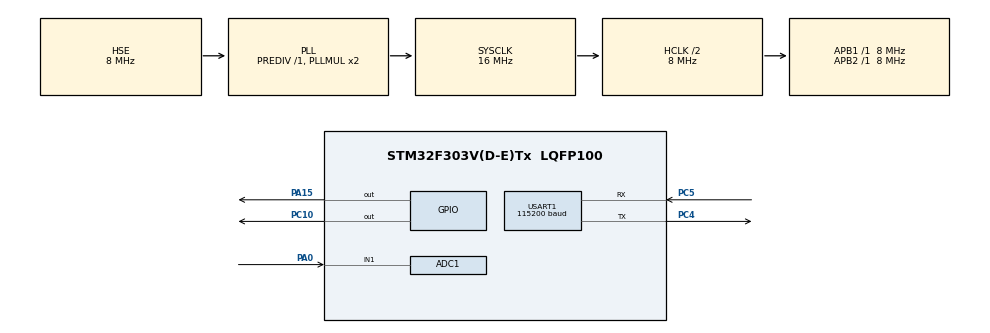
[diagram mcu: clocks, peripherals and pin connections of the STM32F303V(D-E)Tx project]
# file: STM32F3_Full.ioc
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ADC1.Channel-0\#ChannelRegularConversion=ADC_CHANNEL_1
ADC1.NbrOfConversionFlag=1
ADC1.Offset-0\#ChannelRegularConversion=0
ADC1.OffsetNumber-0\#ChannelRegularConversion=ADC_OFFSET_NONE
ADC1.Rank-0\#ChannelRegularConversion=1
ADC1.SamplingTime-0\#ChannelRegularConversion=ADC_SAMPLETIME_1CYCLE_5
ADC1.master=1
FREERTOS.Tasks01=defaultTask,0,128,StartDefaultTask,Default,NULL,Dynamic,NULL,NULL;myTask02,-3,128,StartTask02,Default,NULL,Dynamic,NULL,NULL;myTask03,-3,128,StartTask03,Default,NULL,Dynamic,NULL,NULL
Mcu.Family=STM32F3
Mcu.Name=STM32F303V(D-E)Tx
Mcu.Package=LQFP100
NVIC.ADC1_2_IRQn=true\:5\:0\:false\:false\:true\:true\:true
NVIC.PriorityGroup=NVIC_PRIORITYGROUP_4
NVIC.TIM1_UP_TIM16_IRQn=true\:0\:0\:false\:false\:true\:false\:false
NVIC.TimeBase=TIM1_UP_TIM16_IRQn
NVIC.TimeBaseIP=TIM1
NVIC.USART1_IRQn=true\:5\:0\:false\:false\:true\:true\:true
PA0.Mode=IN1-Single-Ended
PA0.Signal=ADC1_IN1
PA15.Signal=GPIO_Output
PC10.Signal=GPIO_Output
PC4.GPIO_PuPd=GPIO_NOPULL
PC4.Mode=Asynchronous
PC4.Signal=USART1_TX
PC5.GPIO_PuPd=GPIO_NOPULL
PC5.Mode=Asynchronous
PC5.Signal=USART1_RX
PF0-OSC_IN.Mode=HSE-External-Oscillator
PF0-OSC_IN.Signal=RCC_OSC_IN
PF1-OSC_OUT.Mode=HSE-External-Oscillator
PF1-OSC_OUT.Signal=RCC_OSC_OUT
ProjectManager.HeapSize=0x2000
ProjectManager.StackSize=0x4000
ProjectManager.TargetToolchain=TrueSTUDIO
RCC.AHBCLKDivider=RCC_SYSCLK_DIV2
RCC.AHBFreq_Value=8000000
RCC.APB1Freq_Value=8000000
RCC.APB1TimFreq_Value=8000000
RCC.APB2Freq_Value=8000000
RCC.APB2TimFreq_Value=8000000
RCC.CortexFreq_Value=8000000
RCC.HCLKFreq_Value=8000000
RCC.HSE_VALUE=8000000
RCC.HSI_VALUE=8000000
RCC.LSE_VALUE=32768
RCC.PLLSourceVirtual=RCC_PLLSOURCE_HSE
RCC.SYSCLKFreq_VALUE=16000000
RCC.SYSCLKSourceVirtual=RCC_SYSCLKSOURCE_PLLCLK
RCC.USBFreq_Value=16000000
USART1.BaudRate=115200
USART1.VirtualMode-Asynchronous=VM_ASYNC
USART1.WordLength=WORDLENGTH_8B
VP_FREERTOS_VS_ENABLE.Mode=Enabled
VP_SYS_VS_tim1.Mode=TIM1
board=STM32F3_Full

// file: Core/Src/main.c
/**
  ******************************************************************************
  * @file           : main.c
  * @brief          : Main program body
  ******************************************************************************
  * This notice applies to any and all portions of this file
  * that are not between comment pairs USER CODE BEGIN and
  * USER CODE END. Other portions of this file, whether
  * inserted by the user or by software development tools
  * are owned by their respective copyright owners.
  *
  * Copyright (c) 2018 STMicroelectronics International N.V.
  * All rights reserved.
  *
  * Redistribution and use in source and binary forms, with or without
  * modification, are permitted, provided that the following conditions are met:
  *
  * 1. Redistribution of source code must retain the above copyright notice,
  *    this list of conditions and the following disclaimer.
  * 2. Redistributions in binary form must reproduce the above copyright notice,
  *    this list of conditions and the following disclaimer in the documentation
  *    and/or other materials provided with the distribution.
  * 3. Neither the name of STMicroelectronics nor the names of other
  *    contributors to this software may be used to endorse or promote products
  *    derived from this software without specific written permission.
  * 4. This software, including modifications and/or derivative works of this
  *    software, must execute solely and exclusively on microcontroller or
  *    microprocessor devices manufactured by or for STMicroelectronics.
  * 5. Redistribution and use of this software other than as permitted under
  *    this license is void and will automatically terminate your rights under
  *    this license.
  *
  * THIS SOFTWARE IS PROVIDED BY STMICROELECTRONICS AND CONTRIBUTORS "AS IS"
  * AND ANY EXPRESS, IMPLIED OR STATUTORY WARRANTIES, INCLUDING, BUT NOT
  * LIMITED TO, THE IMPLIED WARRANTIES OF MERCHANTABILITY, FITNESS FOR A
  * PARTICULAR PURPOSE AND NON-INFRINGEMENT OF THIRD PARTY INTELLECTUAL PROPERTY
  * RIGHTS ARE DISCLAIMED TO THE FULLEST EXTENT PERMITTED BY LAW. IN NO EVENT
  * SHALL STMICROELECTRONICS OR CONTRIBUTORS BE LIABLE FOR ANY DIRECT, INDIRECT,
  * INCIDENTAL, SPECIAL, EXEMPLARY, OR CONSEQUENTIAL DAMAGES (INCLUDING, BUT NOT
  * LIMITED TO, PROCUREMENT OF SUBSTITUTE GOODS OR SERVICES; LOSS OF USE, DATA,
  * OR PROFITS; OR BUSINESS INTERRUPTION) HOWEVER CAUSED AND ON ANY THEORY OF
  * LIABILITY, WHETHER IN CONTRACT, STRICT LIABILITY, OR TORT (INCLUDING
  * NEGLIGENCE OR OTHERWISE) ARISING IN ANY WAY OUT OF THE USE OF THIS SOFTWARE,
  * EVEN IF ADVISED OF THE POSSIBILITY OF SUCH DAMAGE.
  *
  ******************************************************************************
  */
#include "main.h"
#include "stm32f3xx_hal.h"
#include "cmsis_os.h"

/* USER CODE BEGIN Includes */
#include <stdio.h>
#include <string.h>
/* USER CODE END Includes */

ADC_HandleTypeDef hadc1;

UART_HandleTypeDef huart1;

osThreadId defaultTaskHandle;
osThreadId myTask02Handle;
osThreadId myTask03Handle;

/* USER CODE BEGIN PV */
/* Private variables ---------------------------------------------------------*/

/* USER CODE END PV */

void SystemClock_Config(void);
static void MX_GPIO_Init(void);
static void MX_ADC1_Init(void);
static void MX_USART1_UART_Init(void);
void StartDefaultTask(void const * argument);
void StartTask02(void const * argument);
void StartTask03(void const * argument);

/* USER CODE BEGIN PFP */
/* Private function prototypes -----------------------------------------------*/

/* USER CODE END PFP */

int main(void)
{

  /* MCU Configuration----------------------------------------------------------*/

  /* Reset of all peripherals, Initializes the Flash interface and the Systick. */
  HAL_Init();

  /* Configure the system clock */
  SystemClock_Config();

  /* Initialize all configured peripherals */
  MX_GPIO_Init();
  MX_ADC1_Init();
  MX_USART1_UART_Init();

  /* Create the thread(s) */
  /* definition and creation of defaultTask */
  osThreadDef(defaultTask, StartDefaultTask, osPriorityNormal, 0, 128);
  defaultTaskHandle = osThreadCreate(osThread(defaultTask), NULL);

  /* definition and creation of myTask02 */
  osThreadDef(myTask02, StartTask02, osPriorityIdle, 0, 128);
  myTask02Handle = osThreadCreate(osThread(myTask02), NULL);

  /* definition and creation of myTask03 */
  osThreadDef(myTask03, StartTask03, osPriorityIdle, 0, 128);
  myTask03Handle = osThreadCreate(osThread(myTask03), NULL);

  /* Start scheduler */
  osKernelStart();

  /* We should never get here as control is now taken by the scheduler */

  /* Infinite loop */
  while (1)
  {

  }

}

void SystemClock_Config(void)
{

  RCC_OscInitTypeDef RCC_OscInitStruct;
  RCC_ClkInitTypeDef RCC_ClkInitStruct;
  RCC_PeriphCLKInitTypeDef PeriphClkInit;

    /**Initializes the CPU, AHB and APB busses clocks
    */
  RCC_OscInitStruct.OscillatorType = RCC_OSCILLATORTYPE_HSE;
  RCC_OscInitStruct.HSEState = RCC_HSE_ON;
  RCC_OscInitStruct.HSIState = RCC_HSI_ON;
  RCC_OscInitStruct.PLL.PLLState = RCC_PLL_ON;
  RCC_OscInitStruct.PLL.PLLSource = RCC_PLLSOURCE_HSE;
  RCC_OscInitStruct.PLL.PLLMUL = RCC_PLL_MUL2;
  RCC_OscInitStruct.PLL.PREDIV = RCC_PREDIV_DIV1;
  if (HAL_RCC_OscConfig(&RCC_OscInitStruct) != HAL_OK)
  {
    _Error_Handler(__FILE__, __LINE__);
  }

    /**Initializes the CPU, AHB and APB busses clocks
    */
  RCC_ClkInitStruct.ClockType = RCC_CLOCKTYPE_HCLK|RCC_CLOCKTYPE_SYSCLK
                              |RCC_CLOCKTYPE_PCLK1|RCC_CLOCKTYPE_PCLK2;
  RCC_ClkInitStruct.SYSCLKSource = RCC_SYSCLKSOURCE_PLLCLK;
  RCC_ClkInitStruct.AHBCLKDivider = RCC_SYSCLK_DIV2;
  RCC_ClkInitStruct.APB1CLKDivider = RCC_HCLK_DIV1;
  RCC_ClkInitStruct.APB2CLKDivider = RCC_HCLK_DIV1;

  if (HAL_RCC_ClockConfig(&RCC_ClkInitStruct, FLASH_LATENCY_0) != HAL_OK)
  {
    _Error_Handler(__FILE__, __LINE__);
  }

  PeriphClkInit.PeriphClockSelection = RCC_PERIPHCLK_USART1|RCC_PERIPHCLK_ADC12;
  PeriphClkInit.Usart1ClockSelection = RCC_USART1CLKSOURCE_PCLK2;
  PeriphClkInit.Adc12ClockSelection = RCC_ADC12PLLCLK_DIV1;
  if (HAL_RCCEx_PeriphCLKConfig(&PeriphClkInit) != HAL_OK)
  {
    _Error_Handler(__FILE__, __LINE__);
  }

    /**Configure the Systick interrupt time
    */
  HAL_SYSTICK_Config(HAL_RCC_GetHCLKFreq()/1000);

    /**Configure the Systick
    */
  HAL_SYSTICK_CLKSourceConfig(SYSTICK_CLKSOURCE_HCLK);

  /* SysTick_IRQn interrupt configuration */
  HAL_NVIC_SetPriority(SysTick_IRQn, 15, 0);
}

/* ADC1 init function */
static void MX_ADC1_Init(void)
{

  ADC_MultiModeTypeDef multimode;
  ADC_ChannelConfTypeDef sConfig;

    /**Common config
    */
  hadc1.Instance = ADC1;
  hadc1.Init.ClockPrescaler = ADC_CLOCK_ASYNC_DIV1;
  hadc1.Init.Resolution = ADC_RESOLUTION_12B;
  hadc1.Init.ScanConvMode = ADC_SCAN_DISABLE;
  hadc1.Init.ContinuousConvMode = DISABLE;
  hadc1.Init.DiscontinuousConvMode = DISABLE;
  hadc1.Init.ExternalTrigConvEdge = ADC_EXTERNALTRIGCONVEDGE_NONE;
  hadc1.Init.ExternalTrigConv = ADC_SOFTWARE_START;
  hadc1.Init.DataAlign = ADC_DATAALIGN_RIGHT;
  hadc1.Init.NbrOfConversion = 1;
  hadc1.Init.DMAContinuousRequests = DISABLE;
  hadc1.Init.EOCSelection = ADC_EOC_SINGLE_CONV;
  hadc1.Init.LowPowerAutoWait = DISABLE;
  hadc1.Init.Overrun = ADC_OVR_DATA_OVERWRITTEN;
  if (HAL_ADC_Init(&hadc1) != HAL_OK)
  {
    _Error_Handler(__FILE__, __LINE__);
  }

    /**Configure the ADC multi-mode
    */
  multimode.Mode = ADC_MODE_INDEPENDENT;
  if (HAL_ADCEx_MultiModeConfigChannel(&hadc1, &multimode) != HAL_OK)
  {
    _Error_Handler(__FILE__, __LINE__);
  }

    /**Configure Regular Channel
    */
  sConfig.Channel = ADC_CHANNEL_1;
  sConfig.Rank = ADC_REGULAR_RANK_1;
  sConfig.SingleDiff = ADC_SINGLE_ENDED;
  sConfig.SamplingTime = ADC_SAMPLETIME_1CYCLE_5;
  sConfig.OffsetNumber = ADC_OFFSET_NONE;
  sConfig.Offset = 0;
  if (HAL_ADC_ConfigChannel(&hadc1, &sConfig) != HAL_OK)
  {
    _Error_Handler(__FILE__, __LINE__);
  }

}

/* USART1 init function */
static void MX_USART1_UART_Init(void)
{

  huart1.Instance = USART1;
  huart1.Init.BaudRate = 115200;
  huart1.Init.WordLength = UART_WORDLENGTH_8B;
  huart1.Init.StopBits = UART_STOPBITS_1;
  huart1.Init.Parity = UART_PARITY_NONE;
  huart1.Init.Mode = UART_MODE_TX_RX;
  huart1.Init.HwFlowCtl = UART_HWCONTROL_NONE;
  huart1.Init.OverSampling = UART_OVERSAMPLING_16;
  huart1.Init.OneBitSampling = UART_ONE_BIT_SAMPLE_DISABLE;
  huart1.AdvancedInit.AdvFeatureInit = UART_ADVFEATURE_NO_INIT;
  if (HAL_UART_Init(&huart1) != HAL_OK)
  {
    _Error_Handler(__FILE__, __LINE__);
  }

}

/** Configure pins as
        * Analog
        * Input
        * Output
        * EVENT_OUT
        * EXTI
*/
static void MX_GPIO_Init(void)
{

  GPIO_InitTypeDef GPIO_InitStruct;

  /* GPIO Ports Clock Enable */
  __HAL_RCC_GPIOF_CLK_ENABLE();
  __HAL_RCC_GPIOA_CLK_ENABLE();
  __HAL_RCC_GPIOC_CLK_ENABLE();

  /*Configure GPIO pin Output Level */
  HAL_GPIO_WritePin(GPIOA, GPIO_PIN_15, GPIO_PIN_RESET);

  /*Configure GPIO pin Output Level */
  HAL_GPIO_WritePin(GPIOC, GPIO_PIN_10, GPIO_PIN_RESET);

  /*Configure GPIO pin : PA15 */
  GPIO_InitStruct.Pin = GPIO_PIN_15;
  GPIO_InitStruct.Mode = GPIO_MODE_OUTPUT_PP;
  GPIO_InitStruct.Pull = GPIO_NOPULL;
  GPIO_InitStruct.Speed = GPIO_SPEED_FREQ_LOW;
  HAL_GPIO_Init(GPIOA, &GPIO_InitStruct);

  /*Configure GPIO pin : PC10 */
  GPIO_InitStruct.Pin = GPIO_PIN_10;
  GPIO_InitStruct.Mode = GPIO_MODE_OUTPUT_PP;
  GPIO_InitStruct.Pull = GPIO_NOPULL;
  GPIO_InitStruct.Speed = GPIO_SPEED_FREQ_LOW;
  HAL_GPIO_Init(GPIOC, &GPIO_InitStruct);

}

/* StartDefaultTask function */
void StartDefaultTask(void const * argument)
{

  /* USER CODE BEGIN 5 */
  /* Infinite loop */
  for(;;)
  {
	HAL_GPIO_TogglePin(GPIOA, GPIO_PIN_15);
	printf("ledON");
    osDelay(1000);
  }
  /* USER CODE END 5 */
}

/* StartTask02 function */
void StartTask02(void const * argument)
{
  for(;;)
  {
    osDelay(1);
  }
}

/* StartTask03 function */
void StartTask03(void const * argument)
{
  for(;;)
  {
    osDelay(1);
  }
}

void HAL_TIM_PeriodElapsedCallback(TIM_HandleTypeDef *htim)
{
  if (htim->Instance == TIM1) {
    HAL_IncTick();
  }
}

void _Error_Handler(char *file, int line)
{
  while(1)
  {
  }
}

/************************ (C) COPYRIGHT STMicroelectronics *****END OF FILE****/
